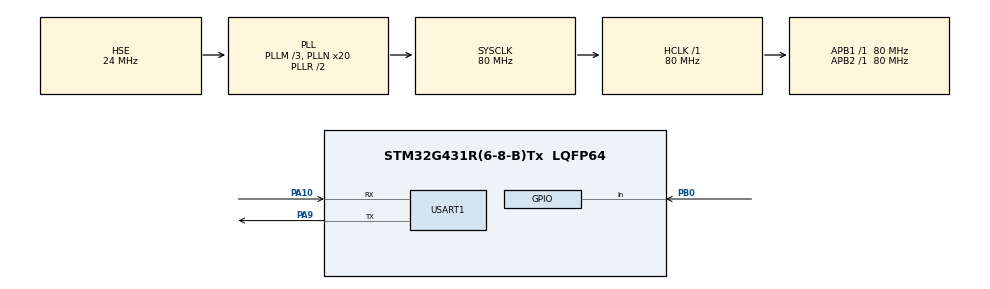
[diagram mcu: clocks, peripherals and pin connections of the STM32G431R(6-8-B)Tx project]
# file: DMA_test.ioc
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Dma.MEMTOMEM.0.Direction=DMA_MEMORY_TO_MEMORY
Dma.MEMTOMEM.0.EventEnable=DISABLE
Dma.MEMTOMEM.0.Instance=DMA1_Channel1
Dma.MEMTOMEM.0.MemDataAlignment=DMA_MDATAALIGN_BYTE
Dma.MEMTOMEM.0.MemInc=DMA_MINC_ENABLE
Dma.MEMTOMEM.0.Mode=DMA_NORMAL
Dma.MEMTOMEM.0.PeriphDataAlignment=DMA_PDATAALIGN_BYTE
Dma.MEMTOMEM.0.PeriphInc=DMA_PINC_ENABLE
Dma.MEMTOMEM.0.Polarity=HAL_DMAMUX_REQ_GEN_RISING
Dma.MEMTOMEM.0.Priority=DMA_PRIORITY_MEDIUM
Dma.MEMTOMEM.0.RequestNumber=1
Dma.MEMTOMEM.0.SignalID=NONE
Dma.MEMTOMEM.0.SyncEnable=DISABLE
Dma.MEMTOMEM.0.SyncPolarity=HAL_DMAMUX_SYNC_NO_EVENT
Dma.MEMTOMEM.0.SyncRequestNumber=1
Dma.MEMTOMEM.0.SyncSignalID=NONE
Dma.Request0=MEMTOMEM
Mcu.Family=STM32G4
Mcu.Name=STM32G431R(6-8-B)Tx
Mcu.Package=LQFP64
NVIC.DMA1_Channel1_IRQn=true\:0\:0\:false\:false\:true\:true\:true\:true
NVIC.PriorityGroup=NVIC_PRIORITYGROUP_4
PA10.Mode=Asynchronous
PA10.Signal=USART1_RX
PA13.Mode=Serial_Wire
PA13.Signal=SYS_JTMS-SWDIO
PA14.Mode=Serial_Wire
PA14.Signal=SYS_JTCK-SWCLK
PA9.Mode=Asynchronous
PA9.Signal=USART1_TX
PB0.GPIO_PuPd=GPIO_PULLUP
PB0.Signal=GPIO_Input
PF0-OSC_IN.Mode=HSE-External-Oscillator
PF0-OSC_IN.Signal=RCC_OSC_IN
PF1-OSC_OUT.Mode=HSE-External-Oscillator
PF1-OSC_OUT.Signal=RCC_OSC_OUT
ProjectManager.HeapSize=0x200
ProjectManager.StackSize=0x400
ProjectManager.TargetToolchain=MDK-ARM V5.32
RCC.ADC12Freq_Value=80000000
RCC.AHBFreq_Value=80000000
RCC.APB1Freq_Value=80000000
RCC.APB1TimFreq_Value=80000000
RCC.APB2Freq_Value=80000000
RCC.APB2TimFreq_Value=80000000
RCC.CortexFreq_Value=80000000
RCC.EXTERNAL_CLOCK_VALUE=12288000
RCC.HCLKFreq_Value=80000000
RCC.HSE_VALUE=24000000
RCC.HSI48_VALUE=48000000
RCC.HSI_VALUE=16000000
RCC.LSE_VALUE=32768
RCC.PLLM=RCC_PLLM_DIV3
RCC.PLLN=20
RCC.PLLSourceVirtual=RCC_PLLSOURCE_HSE
RCC.SYSCLKFreq_VALUE=80000000
RCC.SYSCLKSource=RCC_SYSCLKSOURCE_PLLCLK
RCC.USBFreq_Value=80000000
RCC.VCOOutputFreq_Value=160000000
TIM1.Prescaler=80
USART1.VirtualMode-Asynchronous=VM_ASYNC
VP_SYS_VS_DBSignals.Mode=DisableDeadBatterySignals
VP_TIM1_VS_ClockSourceINT.Mode=Internal
board=custom

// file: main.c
/* USER CODE BEGIN Header */
/**
 ******************************************************************************
 * @file           : main.c
 * @brief          : Main program body
 ******************************************************************************
 * @attention
 *
 * Copyright (c) 2023 STMicroelectronics.
 * All rights reserved.
 *
 * This software is licensed under terms that can be found in the LICENSE file
 * in the root directory of this software component.
 * If no LICENSE file comes with this software, it is provided AS-IS.
 *
 ******************************************************************************
 */
/* USER CODE END Header */
#include "main.h"
#include "dma.h"
#include "tim.h"
#include "usart.h"
#include "gpio.h"

/* USER CODE BEGIN Includes */
#include <stdio.h>
#include <string.h>
#include "lcd.h"
#include "stdbool.h"
/* USER CODE END Includes */

/* USER CODE BEGIN PV */
#define ARRAY_SIZE 1000

uint32_t array[ARRAY_SIZE];
uint32_t destination[ARRAY_SIZE];
uint32_t start, end;
uint32_t dma_time, cpu_time;
/* USER CODE END PV */

void SystemClock_Config(void);
/* USER CODE BEGIN PFP */
void LED_Disp(unsigned char dsLED)
{
  HAL_GPIO_WritePin(GPIOC, GPIO_PIN_All, GPIO_PIN_SET);
  HAL_GPIO_WritePin(GPIOC, dsLED << 8, GPIO_PIN_RESET);
  HAL_GPIO_WritePin(GPIOD, GPIO_PIN_2, GPIO_PIN_SET);
  HAL_GPIO_WritePin(GPIOD, GPIO_PIN_2, GPIO_PIN_RESET);
}

#define LONG_PRESS_TIME 500

struct keys
{
  GPIO_TypeDef *key_port;
  uint16_t key_pin;
  bool pressed_flag;
  unsigned int press_time;
  unsigned int press_start_time;
};

struct keys key[4] = {0};

void key_init(void)
{
  key[0].key_port = GPIOB;
  key[1].key_port = GPIOB;
  key[2].key_port = GPIOB;
  key[3].key_port = GPIOA;
  key[0].key_pin = GPIO_PIN_0;
  key[1].key_pin = GPIO_PIN_1;
  key[2].key_pin = GPIO_PIN_2;
  key[3].key_pin = GPIO_PIN_0;
}

void key_scan(void)
{

  // 扫描按键
  for (int i = 0; i < 1; i++)
  {
    if (HAL_GPIO_ReadPin(key[i].key_port, key[i].key_pin) == 0)
    {
      HAL_Delay(10); // 按键消抖
      if (HAL_GPIO_ReadPin(key[i].key_port, key[i].key_pin) == 0)
      {
        key[i].press_start_time = HAL_GetTick();
        while (HAL_GPIO_ReadPin(key[i].key_port, key[i].key_pin) == 0)
          ;
        key[i].pressed_flag = 1; // 按键按下
        // 计算按下时间
        key[i].press_time = HAL_GetTick() - key[i].press_start_time;
      }
    }
  }
}
/* USER CODE END PFP */

/* USER CODE BEGIN 0 */
void fill_array(void)
{
  for (int i = 0; i < ARRAY_SIZE; i++)
  {
    array[i] = i;
  }
}

void dma_transfer(void)
{
  TIM1->CNT = 0;
  start = TIM1->CNT;
  for (int i = 0; i < 1000; i++)
  {
    HAL_DMA_Start(&hdma_memtomem_dma1_channel1, (uint32_t)array, (uint32_t)destination, ARRAY_SIZE);
    HAL_DMA_PollForTransfer(&hdma_memtomem_dma1_channel1, HAL_DMA_FULL_TRANSFER, HAL_MAX_DELAY);
  }
  end = TIM1->CNT;
  dma_time = end - start;
}

void cpu_transfer(void)
{
  TIM1->CNT = 0;
  start = TIM1->CNT;
  for (int j = 0; j < 1000; j++)
  {
    for (int i = 0; i < ARRAY_SIZE; i++)
    {
      destination[i] = array[i];
    }
  }
  end = TIM1->CNT;
  cpu_time = end - start;
}

void key_proc(void)
{
  if (key[0].pressed_flag == 1) // 按键按下
  {
    char buffer[50];
    sprintf(buffer, "Transferring %.2f MB\r\n", (ARRAY_SIZE * 4 * 1000) / (1024.0 * 1024.0)); // 4 bytes per uint32_t
    HAL_UART_Transmit(&huart1, (uint8_t *)buffer, strlen(buffer), HAL_MAX_DELAY);

    dma_transfer();
    cpu_transfer();

    sprintf(buffer, "DMA time: %d us, CPU time: %d us\r\n", dma_time, cpu_time);
    HAL_UART_Transmit(&huart1, (uint8_t *)buffer, strlen(buffer), HAL_MAX_DELAY);

    sprintf(buffer, "Transfer Complete\r\n");
    HAL_UART_Transmit(&huart1, (uint8_t *)buffer, strlen(buffer), HAL_MAX_DELAY);

    sprintf(buffer, "DMA is %.2f times faster than CPU\r\n", cpu_time / (float)dma_time);
    HAL_UART_Transmit(&huart1, (uint8_t *)buffer, strlen(buffer), HAL_MAX_DELAY);

    key[0].pressed_flag = 0;
  }
}
/* USER CODE END 0 */

int main(void)
{

  /* MCU Configuration--------------------------------------------------------*/

  /* Reset of all peripherals, Initializes the Flash interface and the Systick. */
  HAL_Init();

  /* Configure the system clock */
  SystemClock_Config();

  /* Initialize all configured peripherals */
  MX_GPIO_Init();
  MX_DMA_Init();
  MX_USART1_UART_Init();
  MX_TIM1_Init();
  /* USER CODE BEGIN 2 */
  LCD_Init();
  LCD_Clear(Black); // 清屏函数
  LCD_SetBackColor(Black);
  LCD_SetTextColor(White);

  LED_Disp(0x00);

  HAL_TIM_Base_Start(&htim1);

  key_init();

  fill_array();
  /* USER CODE END 2 */

  /* Infinite loop */
  while (1)
  {

    /* USER CODE BEGIN 3 */
    key_scan(); // 调用按键扫描
    key_proc();
  }
  /* USER CODE END 3 */
}

void SystemClock_Config(void)
{
  RCC_OscInitTypeDef RCC_OscInitStruct = {0};
  RCC_ClkInitTypeDef RCC_ClkInitStruct = {0};

  /** Configure the main internal regulator output voltage
   */
  HAL_PWREx_ControlVoltageScaling(PWR_REGULATOR_VOLTAGE_SCALE1);

  /** Initializes the RCC Oscillators according to the specified parameters
   * in the RCC_OscInitTypeDef structure.
   */
  RCC_OscInitStruct.OscillatorType = RCC_OSCILLATORTYPE_HSE;
  RCC_OscInitStruct.HSEState = RCC_HSE_ON;
  RCC_OscInitStruct.PLL.PLLState = RCC_PLL_ON;
  RCC_OscInitStruct.PLL.PLLSource = RCC_PLLSOURCE_HSE;
  RCC_OscInitStruct.PLL.PLLM = RCC_PLLM_DIV3;
  RCC_OscInitStruct.PLL.PLLN = 20;
  RCC_OscInitStruct.PLL.PLLP = RCC_PLLP_DIV2;
  RCC_OscInitStruct.PLL.PLLQ = RCC_PLLQ_DIV2;
  RCC_OscInitStruct.PLL.PLLR = RCC_PLLR_DIV2;
  if (HAL_RCC_OscConfig(&RCC_OscInitStruct) != HAL_OK)
  {
    Error_Handler();
  }

  /** Initializes the CPU, AHB and APB buses clocks
   */
  RCC_ClkInitStruct.ClockType = RCC_CLOCKTYPE_HCLK | RCC_CLOCKTYPE_SYSCLK | RCC_CLOCKTYPE_PCLK1 | RCC_CLOCKTYPE_PCLK2;
  RCC_ClkInitStruct.SYSCLKSource = RCC_SYSCLKSOURCE_PLLCLK;
  RCC_ClkInitStruct.AHBCLKDivider = RCC_SYSCLK_DIV1;
  RCC_ClkInitStruct.APB1CLKDivider = RCC_HCLK_DIV1;
  RCC_ClkInitStruct.APB2CLKDivider = RCC_HCLK_DIV1;

  if (HAL_RCC_ClockConfig(&RCC_ClkInitStruct, FLASH_LATENCY_2) != HAL_OK)
  {
    Error_Handler();
  }
}

void Error_Handler(void)
{
  __disable_irq();
  while (1)
  {
  }
}
